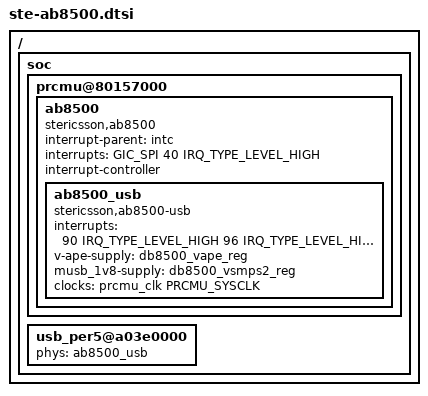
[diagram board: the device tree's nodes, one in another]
// SPDX-License-Identifier: GPL-2.0-or-later
/*
 * Copyright 2012 Linaro Ltd
 */

/ {
	soc {
		prcmu@80157000 {
			ab8500 {
				compatible = "stericsson,ab8500";
				interrupt-parent = <&intc>;
				interrupts = <GIC_SPI 40 IRQ_TYPE_LEVEL_HIGH>;
				interrupt-controller;
				#interrupt-cells = <2>;

				ab8500_usb: ab8500_usb {
					#phy-cells = <0>;
					compatible = "stericsson,ab8500-usb";
					interrupts = < 90 IRQ_TYPE_LEVEL_HIGH
						       96 IRQ_TYPE_LEVEL_HIGH
						       14 IRQ_TYPE_LEVEL_HIGH
						       15 IRQ_TYPE_LEVEL_HIGH
						       79 IRQ_TYPE_LEVEL_HIGH
						       74 IRQ_TYPE_LEVEL_HIGH
						       75 IRQ_TYPE_LEVEL_HIGH>;
					interrupt-names = "ID_WAKEUP_R",
							  "ID_WAKEUP_F",
							  "VBUS_DET_F",
							  "VBUS_DET_R",
							  "USB_LINK_STATUS",
							  "USB_ADP_PROBE_PLUG",
							  "USB_ADP_PROBE_UNPLUG";
					//vddulpivio18-supply = <&ab8500_ldo_intcore_reg>;
					v-ape-supply = <&db8500_vape_reg>;
					musb_1v8-supply = <&db8500_vsmps2_reg>;
					clocks = <&prcmu_clk PRCMU_SYSCLK>;
					clock-names = "sysclk";
				};
			};
		};

		usb_per5@a03e0000 {
			phys = <&ab8500_usb>;
			phy-names = "usb";
		};
	};
};
